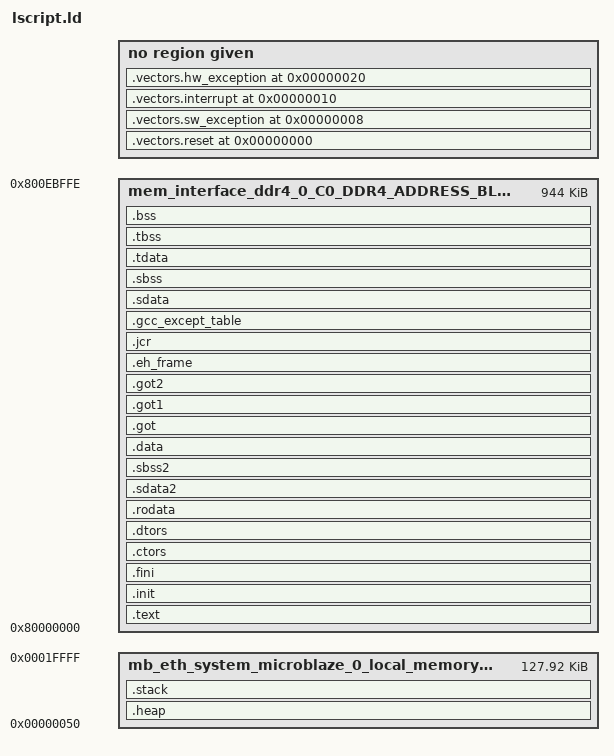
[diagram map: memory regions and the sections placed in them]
/*******************************************************************/
/*                                                                 */
/* This file is automatically generated by linker script generator.*/
/*                                                                 */
/* Version:                                 */
/*                                                                 */
/* Copyright (c) 2010-2016 Xilinx, Inc.  All rights reserved.      */
/*                                                                 */
/* Description : MicroBlaze Linker Script                          */
/*                                                                 */
/*******************************************************************/

_STACK_SIZE = DEFINED(_STACK_SIZE) ? _STACK_SIZE : 0xA000;
_HEAP_SIZE = DEFINED(_HEAP_SIZE) ? _HEAP_SIZE : 0xA000;

/* Define Memories in the system */

MEMORY
{
   mb_eth_system_microblaze_0_local_memory_ilmb_bram_if_cntlr_Mem_mb_eth_system_microblaze_0_local_memory_dlmb_bram_if_cntlr_Mem : ORIGIN = 0x50, LENGTH = 0x1FFB0
   mem_interface_ddr4_0_C0_DDR4_ADDRESS_BLOCK : ORIGIN = 0x80000000, LENGTH = 0xebfff
}

/* Specify the default entry point to the program */

ENTRY(_start)

/* Define the sections, and where they are mapped in memory */

SECTIONS
{
.vectors.reset 0x0 : {
   KEEP (*(.vectors.reset))
} 

.vectors.sw_exception 0x8 : {
   KEEP (*(.vectors.sw_exception))
} 

.vectors.interrupt 0x10 : {
   KEEP (*(.vectors.interrupt))
} 

.vectors.hw_exception 0x20 : {
   KEEP (*(.vectors.hw_exception))
} 

.text : {
   *(.text)
   *(.text.*)
   *(.gnu.linkonce.t.*)
} > mem_interface_ddr4_0_C0_DDR4_ADDRESS_BLOCK

.init : {
   KEEP (*(.init))
} > mem_interface_ddr4_0_C0_DDR4_ADDRESS_BLOCK

.fini : {
   KEEP (*(.fini))
} > mem_interface_ddr4_0_C0_DDR4_ADDRESS_BLOCK

.ctors : {
   __CTOR_LIST__ = .;
   ___CTORS_LIST___ = .;
   KEEP (*crtbegin.o(.ctors))
   KEEP (*(EXCLUDE_FILE(*crtend.o) .ctors))
   KEEP (*(SORT(.ctors.*)))
   KEEP (*(.ctors))
   __CTOR_END__ = .;
   ___CTORS_END___ = .;
} > mem_interface_ddr4_0_C0_DDR4_ADDRESS_BLOCK

.dtors : {
   __DTOR_LIST__ = .;
   ___DTORS_LIST___ = .;
   KEEP (*crtbegin.o(.dtors))
   KEEP (*(EXCLUDE_FILE(*crtend.o) .dtors))
   KEEP (*(SORT(.dtors.*)))
   KEEP (*(.dtors))
   PROVIDE(__DTOR_END__ = .);
   PROVIDE(___DTORS_END___ = .);
} > mem_interface_ddr4_0_C0_DDR4_ADDRESS_BLOCK

.rodata : {
   __rodata_start = .;
   *(.rodata)
   *(.rodata.*)
   *(.gnu.linkonce.r.*)
   __rodata_end = .;
} > mem_interface_ddr4_0_C0_DDR4_ADDRESS_BLOCK

.sdata2 : {
   . = ALIGN(8);
   __sdata2_start = .;
   *(.sdata2)
   *(.sdata2.*)
   *(.gnu.linkonce.s2.*)
   . = ALIGN(8);
   __sdata2_end = .;
} > mem_interface_ddr4_0_C0_DDR4_ADDRESS_BLOCK

.sbss2 : {
   __sbss2_start = .;
   *(.sbss2)
   *(.sbss2.*)
   *(.gnu.linkonce.sb2.*)
   __sbss2_end = .;
} > mem_interface_ddr4_0_C0_DDR4_ADDRESS_BLOCK

.data : {
   . = ALIGN(4);
   __data_start = .;
   *(.data)
   *(.data.*)
   *(.gnu.linkonce.d.*)
   __data_end = .;
} > mem_interface_ddr4_0_C0_DDR4_ADDRESS_BLOCK

.got : {
   *(.got)
} > mem_interface_ddr4_0_C0_DDR4_ADDRESS_BLOCK

.got1 : {
   *(.got1)
} > mem_interface_ddr4_0_C0_DDR4_ADDRESS_BLOCK

.got2 : {
   *(.got2)
} > mem_interface_ddr4_0_C0_DDR4_ADDRESS_BLOCK

.eh_frame : {
   *(.eh_frame)
} > mem_interface_ddr4_0_C0_DDR4_ADDRESS_BLOCK

.jcr : {
   *(.jcr)
} > mem_interface_ddr4_0_C0_DDR4_ADDRESS_BLOCK

.gcc_except_table : {
   *(.gcc_except_table)
} > mem_interface_ddr4_0_C0_DDR4_ADDRESS_BLOCK

.sdata : {
   . = ALIGN(8);
   __sdata_start = .;
   *(.sdata)
   *(.sdata.*)
   *(.gnu.linkonce.s.*)
   __sdata_end = .;
} > mem_interface_ddr4_0_C0_DDR4_ADDRESS_BLOCK

.sbss (NOLOAD) : {
   . = ALIGN(4);
   __sbss_start = .;
   *(.sbss)
   *(.sbss.*)
   *(.gnu.linkonce.sb.*)
   . = ALIGN(8);
   __sbss_end = .;
} > mem_interface_ddr4_0_C0_DDR4_ADDRESS_BLOCK

.tdata : {
   __tdata_start = .;
   *(.tdata)
   *(.tdata.*)
   *(.gnu.linkonce.td.*)
   __tdata_end = .;
} > mem_interface_ddr4_0_C0_DDR4_ADDRESS_BLOCK

.tbss : {
   __tbss_start = .;
   *(.tbss)
   *(.tbss.*)
   *(.gnu.linkonce.tb.*)
   __tbss_end = .;
} > mem_interface_ddr4_0_C0_DDR4_ADDRESS_BLOCK

.bss (NOLOAD) : {
   . = ALIGN(4);
   __bss_start = .;
   *(.bss)
   *(.bss.*)
   *(.gnu.linkonce.b.*)
   *(COMMON)
   . = ALIGN(4);
   __bss_end = .;
} > mem_interface_ddr4_0_C0_DDR4_ADDRESS_BLOCK

_SDA_BASE_ = __sdata_start + ((__sbss_end - __sdata_start) / 2 );

_SDA2_BASE_ = __sdata2_start + ((__sbss2_end - __sdata2_start) / 2 );

/* Generate Stack and Heap definitions */

.heap (NOLOAD) : {
   . = ALIGN(8);
   _heap = .;
   _heap_start = .;
   . += _HEAP_SIZE;
   _heap_end = .;
} > mb_eth_system_microblaze_0_local_memory_ilmb_bram_if_cntlr_Mem_mb_eth_system_microblaze_0_local_memory_dlmb_bram_if_cntlr_Mem

.stack (NOLOAD) : {
   _stack_end = .;
   . += _STACK_SIZE;
   . = ALIGN(8);
   _stack = .;
   __stack = _stack;
} > mb_eth_system_microblaze_0_local_memory_ilmb_bram_if_cntlr_Mem_mb_eth_system_microblaze_0_local_memory_dlmb_bram_if_cntlr_Mem

_end = .;
}

